VERSION "37805-RAD-A820-M1 PCM RECEIVE FRAMES"

NS_ :

BS_:
BU_: PCM XXX HDS INFERRED PROVEN

CM_ SG_ 212 FUEL_LEVEL_SENSOR_VOLTAGE "Nominal volts = B4*5/256; exact factory coefficient unresolved. PCM internally stores B4*4 counts.";
CM_ SG_ 212 A_C_SWITCH "A/C switch/request state.";
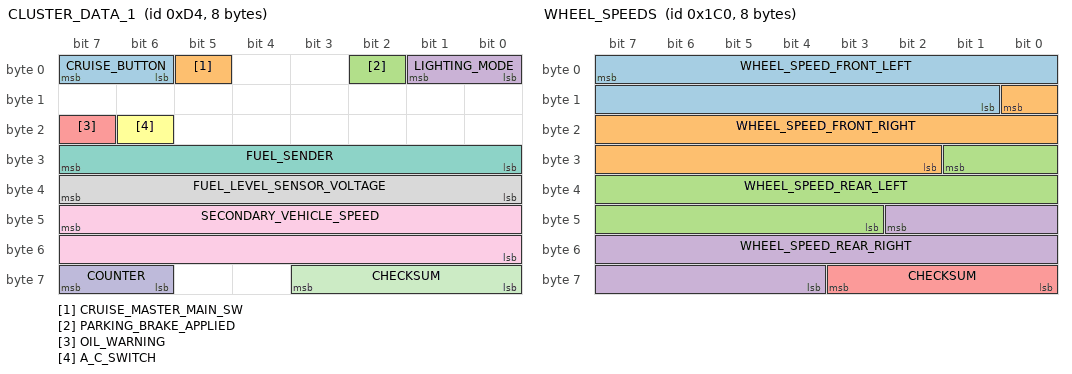
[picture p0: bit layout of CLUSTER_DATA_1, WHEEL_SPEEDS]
BO_ 212 CLUSTER_DATA_1: 8 CLUSTER
 SG_ CRUISE_BUTTON : 7|2@0+ (1,0) [0|3] "code" PCM,PROVEN
 SG_ CRUISE_MASTER_MAIN_SW : 5|1@0+ (1,0) [0|1] "bool" PCM,HDS
 SG_ PARKING_BRAKE_APPLIED : 2|1@0+ (1,0) [0|1] "bool" PCM,PROVEN
 SG_ LIGHTING_MODE : 1|2@0+ (1,0) [0|3] "code" PCM,PROVEN
 SG_ OIL_WARNING : 23|1@0+ (1,0) [0|1] "bool" PCM,PROVEN
 SG_ A_C_SWITCH : 22|1@0+ (1,0) [0|1] "bool" PCM,HDS
 SG_ FUEL_SENDER : 31|8@0+ (1,0) [0|255] "raw" PCM,PROVEN
 SG_ FUEL_LEVEL_SENSOR_VOLTAGE : 39|8@0+ (0.01953125,0) [0|4.98046875] "V" PCM,HDS
 SG_ SECONDARY_VEHICLE_SPEED : 47|16@0+ (0.01,0) [0|655.35] "km/h" PCM,PROVEN
 SG_ COUNTER : 63|2@0+ (1,0) [0|3] "count" PCM,PROVEN
 SG_ CHECKSUM : 59|4@0+ (1,0) [0|15] "raw" PCM,PROVEN

VAL_ 212 CRUISE_BUTTON 0 "none" 1 "SET/DECEL" 2 "RESUME/ACCEL" 3 "CANCEL" ;
VAL_ 212 LIGHTING_MODE 0 "off" 1 "parking" 2 "low beam" 3 "high beam" ;

CM_ BO_ 448 "Four 15-bit channels and 0.01 km/h scaling verified in PCM. Legacy wheel-corner assignments are not established by this firmware.";
BO_ 448 WHEEL_SPEEDS: 8 VSA
 SG_ WHEEL_SPEED_FRONT_LEFT : 7|15@0+ (0.01,0) [0|327.67] "km/h" PCM,PROVEN
 SG_ WHEEL_SPEED_FRONT_RIGHT : 8|15@0+ (0.01,0) [0|327.67] "km/h" PCM,PROVEN
 SG_ WHEEL_SPEED_REAR_LEFT : 25|15@0+ (0.01,0) [0|327.67] "km/h" PCM,PROVEN
 SG_ WHEEL_SPEED_REAR_RIGHT : 42|15@0+ (0.01,0) [0|327.67] "km/h" PCM,PROVEN
 SG_ CHECKSUM : 59|4@0+ (1,0) [0|15] "raw" PCM,PROVEN

CM_ SG_ 500 ODOMETER "Raw 24-bit count displayed as km using the supplied Accord research assumption. PCM caches B3:B4 only; full B3:B5 layout and whole-km units are not proven by this receiver.";
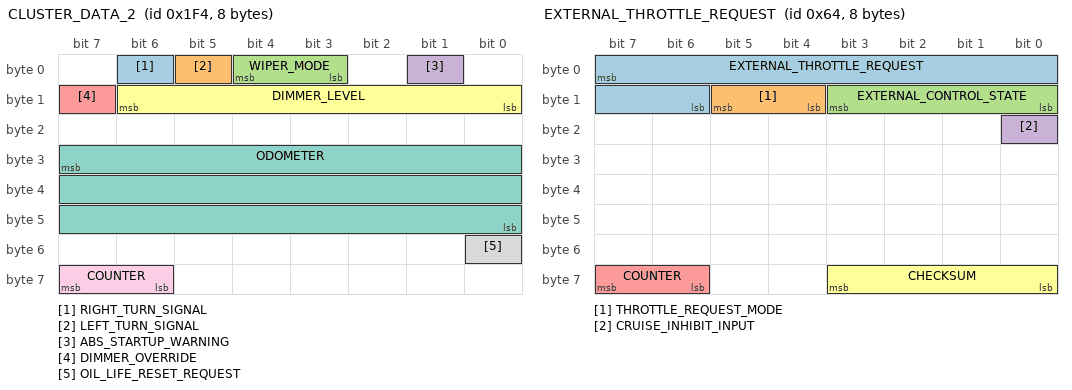
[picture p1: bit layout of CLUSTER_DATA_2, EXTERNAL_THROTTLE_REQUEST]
BO_ 500 CLUSTER_DATA_2: 8 CLUSTER
 SG_ RIGHT_TURN_SIGNAL : 6|1@0+ (1,0) [0|1] "bool" PCM,PROVEN
 SG_ LEFT_TURN_SIGNAL : 5|1@0+ (1,0) [0|1] "bool" PCM,PROVEN
 SG_ WIPER_MODE : 4|2@0+ (1,0) [0|3] "code" PCM,PROVEN
 SG_ ABS_STARTUP_WARNING : 1|1@0+ (1,0) [0|1] "bool" PCM,PROVEN
 SG_ DIMMER_OVERRIDE : 15|1@0+ (1,0) [0|1] "bool" PCM,INFERRED
 SG_ DIMMER_LEVEL : 14|7@0+ (1,0) [0|127] "code" PCM,INFERRED
 SG_ ODOMETER : 31|24@0+ (1,0) [0|16777215] "km" PCM,PROVEN
 SG_ OIL_LIFE_RESET_REQUEST : 48|1@0+ (1,0) [0|1] "bool" PCM,PROVEN
 SG_ COUNTER : 63|2@0+ (1,0) [0|3] "count" PCM,PROVEN

VAL_ 500 WIPER_MODE 0 "off" 1 "intermittent" 2 "low" 3 "high" ;
CM_ SG_ 500 DIMMER_OVERRIDE "Possible maximum-brightness detent/night-dimming cancel";
CM_ SG_ 500 DIMMER_LEVEL "Possible instrument-illumination brightness, values 24,48,77,100";

BO_ 100 EXTERNAL_THROTTLE_REQUEST: 8 XXX
 SG_ EXTERNAL_THROTTLE_REQUEST : 7|10@0+ (0.1,0) [0|102.3] "deg" PCM,PROVEN
 SG_ THROTTLE_REQUEST_MODE : 13|2@0+ (1,0) [0|3] "code" PCM,PROVEN
 SG_ EXTERNAL_CONTROL_STATE : 11|4@0+ (1,0) [0|15] "code" PCM,PROVEN
 SG_ CRUISE_INHIBIT_INPUT : 16|1@0+ (1,0) [0|1] "bool" PCM,PROVEN
 SG_ COUNTER : 63|2@0+ (1,0) [0|3] "count" PCM,PROVEN
 SG_ CHECKSUM : 59|4@0+ (1,0) [0|15] "raw" PCM,PROVEN

VAL_ 100 THROTTLE_REQUEST_MODE 0 "inactive" 1 "minimum" 2 "maximum" 3 "inactive" ;

CM_ BO_ 160 "DISABLED IN THIS FIRMWARE";
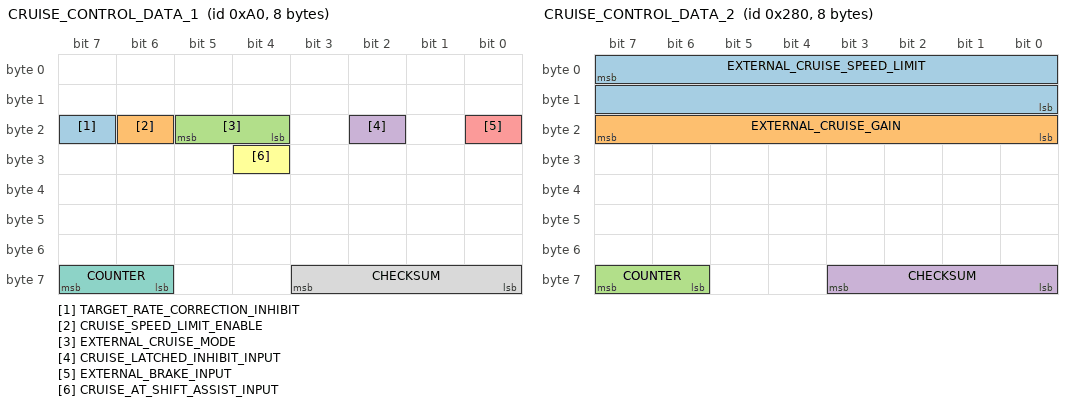
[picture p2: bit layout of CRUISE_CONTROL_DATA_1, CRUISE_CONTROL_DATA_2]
BO_ 160 CRUISE_CONTROL_DATA_1: 8 XXX
 SG_ TARGET_RATE_CORRECTION_INHIBIT : 23|1@0+ (1,0) [0|1] "bool" PCM,PROVEN
 SG_ CRUISE_SPEED_LIMIT_ENABLE : 22|1@0+ (1,0) [0|1] "bool" PCM,PROVEN
 SG_ EXTERNAL_CRUISE_MODE : 21|2@0+ (1,0) [0|3] "code" PCM,PROVEN
 SG_ CRUISE_LATCHED_INHIBIT_INPUT : 18|1@0+ (1,0) [0|1] "bool" PCM,PROVEN
 SG_ EXTERNAL_BRAKE_INPUT : 16|1@0+ (1,0) [0|1] "bool" PCM,PROVEN
 SG_ CRUISE_AT_SHIFT_ASSIST_INPUT : 28|1@0+ (1,0) [0|1] "bool" PCM,PROVEN
 SG_ COUNTER : 63|2@0+ (1,0) [0|3] "count" PCM,PROVEN
 SG_ CHECKSUM : 59|4@0+ (1,0) [0|15] "raw" PCM,PROVEN

CM_ SG_ 160 CRUISE_SPEED_LIMIT_ENABLE "Applies in cruise mode 0";
VAL_ 160 EXTERNAL_CRUISE_MODE 0 "external variant0" 1 "external variant1" 2 "ordinary cruise" 3 "invalid or fallback" ;

CM_ BO_ 640 "DISABLED IN THIS FIRMWARE";

BO_ 640 CRUISE_CONTROL_DATA_2: 8 XXX
 SG_ EXTERNAL_CRUISE_SPEED_LIMIT : 7|16@0+ (0.01,0) [0|655.35] "km/h" PCM,PROVEN
 SG_ EXTERNAL_CRUISE_GAIN : 23|8@0+ (0.005,0) [0|1.2750000000000001] "ratio" PCM,PROVEN
 SG_ COUNTER : 63|2@0+ (1,0) [0|3] "count" PCM,PROVEN
 SG_ CHECKSUM : 59|4@0+ (1,0) [0|15] "raw" PCM,PROVEN

CM_ BO_ 1065 "DISABLED IN THIS FIRMWARE";
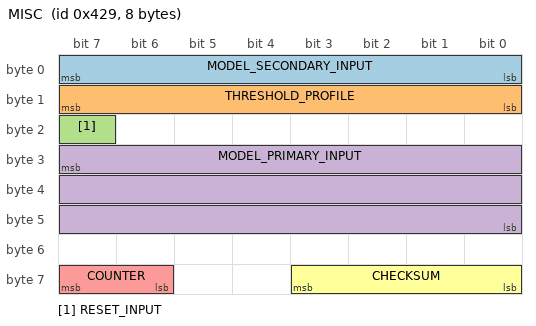
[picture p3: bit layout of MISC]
BO_ 1065 MISC: 8 XXX
 SG_ MODEL_SECONDARY_INPUT : 7|8@0+ (1,0) [0|255] "raw" PCM,INFERRED
 SG_ THRESHOLD_PROFILE : 15|8@0+ (1,0) [0|255] "code" PCM,INFERRED
 SG_ RESET_INPUT : 23|1@0+ (1,0) [0|1] "bool" PCM,INFERRED
 SG_ MODEL_PRIMARY_INPUT : 31|24@0+ (1,0) [0|16777215] "raw" PCM,INFERRED
 SG_ COUNTER : 63|2@0+ (1,0) [0|3] "count" PCM,PROVEN
 SG_ CHECKSUM : 59|4@0+ (1,0) [0|15] "raw" PCM,PROVEN
